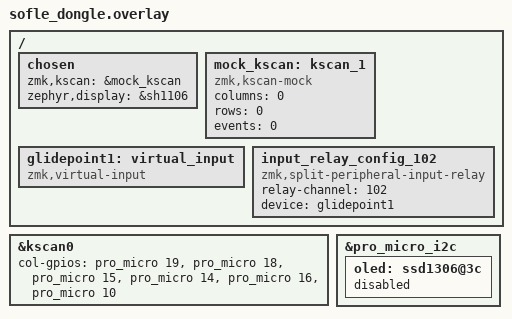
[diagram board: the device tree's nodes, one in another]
#include "sofle.dtsi"
#include "sofle_cirque.dtsi"

/ {
    chosen {
        zmk,kscan = &mock_kscan;
        zephyr,display = &sh1106;
    };

    mock_kscan: kscan_1 {
        compatible = "zmk,kscan-mock";
        columns = <0>;
        rows = <0>;
        events = <0>;
    };
};

&kscan0 {
    col-gpios
        = <&pro_micro 19 GPIO_ACTIVE_HIGH>
        , <&pro_micro 18 GPIO_ACTIVE_HIGH>
        , <&pro_micro 15 GPIO_ACTIVE_HIGH>
        , <&pro_micro 14 GPIO_ACTIVE_HIGH>
        , <&pro_micro 16 GPIO_ACTIVE_HIGH>
        , <&pro_micro 10 GPIO_ACTIVE_HIGH>
        ;
};

// This section is needed for the display or will error during compiling.
&pro_micro_i2c {
    status = "okay";

    oled: ssd1306@3c {
        status = "disabled";
    };
};

// Cirque Trackpad
// Split peripheral input relay module central.
/ {
	glidepoint1: virtual_input {
		compatible = "zmk,virtual-input";
	};

	input_relay_config_102 {
		compatible = "zmk,split-peripheral-input-relay";
		relay-channel = <102>;
		device = <&glidepoint1>;
	};
};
